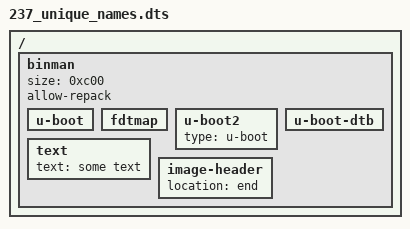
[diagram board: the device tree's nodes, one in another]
// SPDX-License-Identifier: GPL-2.0+

/dts-v1/;

/ {
	#address-cells = <1>;
	#size-cells = <1>;

	binman {
		size = <0xc00>;
		allow-repack;

		u-boot {
		};

		fdtmap {
		};

		u-boot2 {
			type = "u-boot";
		};

		text {
			text = "some text";
		};

		u-boot-dtb {
		};

		image-header {
			location = "end";
		};
	};
};
